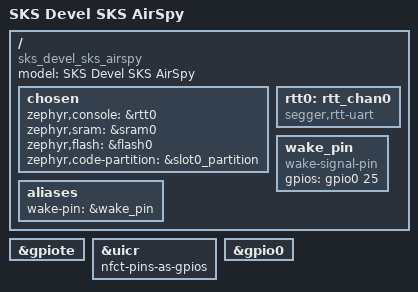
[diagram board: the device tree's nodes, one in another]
/*
 * Copyright (c) 2024 Arne Wendt (@bitmeal)
 *
 * SPDX-License-Identifier: Apache-2.0
 */

/dts-v1/;
#include <nordic/nrf52832_qfaa.dtsi>
#include "sks_devel_sks_airspy-pinctrl.dtsi"
#include <zephyr/dt-bindings/input/input-event-codes.h>

/ {
	model = "SKS Devel SKS AirSpy";
	compatible = "sks_devel_sks_airspy";

	chosen {
		zephyr,console = &rtt0;
		// zephyr,shell-uart = &rtt0;
		// zephyr,uart-mcumgr = &rtt0;
		// zephyr,bt-mon-uart = &rtt0;
		// zephyr,bt-c2h-uart = &rtt0;

		zephyr,sram = &sram0;
		zephyr,flash = &flash0;
		zephyr,code-partition = &slot0_partition;
	};

	rtt0: rtt_chan0 {
		compatible = "segger,rtt-uart";
		status = "okay";
	};

	wake_pin: wake_pin {
		compatible = "wake-signal-pin";
		gpios = <&gpio0 25 GPIO_ACTIVE_HIGH>;
	};
	
	aliases {
		wake-pin = &wake_pin;
	};
};

&gpiote {
	status = "okay";
};

&uicr {
	// gpio-as-nreset;
	nfct-pins-as-gpios;
};

&gpio0 {
	status = "okay";
};

// Include flash partition table.
#include "fstab.dtsi"
